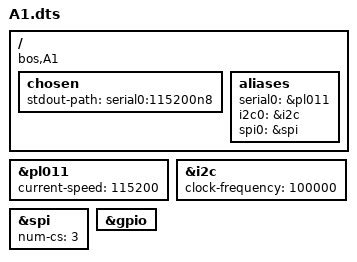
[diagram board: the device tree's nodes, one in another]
// Defining Board lv HW
/dts-v1/;

#include "A1.dtsi"

/ {
    compatible = "bos,A1";
    // model = "BOS Super SoC-A1";
    
    // node들의 주소 지정방식
    //// =>  <address 상위 32비트, address 하위 32비트, size 상위 32비트, size 하위 32비트>
    #address-cells = <2>;                 // 64비트 주소를 표현
    #size-cells = <2>;                    // node가 mapping된 메모리 주소 공간의 크기 표현

    chosen {
        stdout-path = "serial0:115200n8";
    };

    aliases {
        serial0 = &pl011;
        i2c0 = &i2c;
        spi0 = &spi;
    };
};

&pl011 {
    status = "okay";
    current-speed = <115200>;
};

&i2c {
    status = "okay";
    clock-frequency = <100000>;
};

&spi {
    status = "okay";
    num-cs = <3>;
};

&gpio {
    status = "okay";
};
